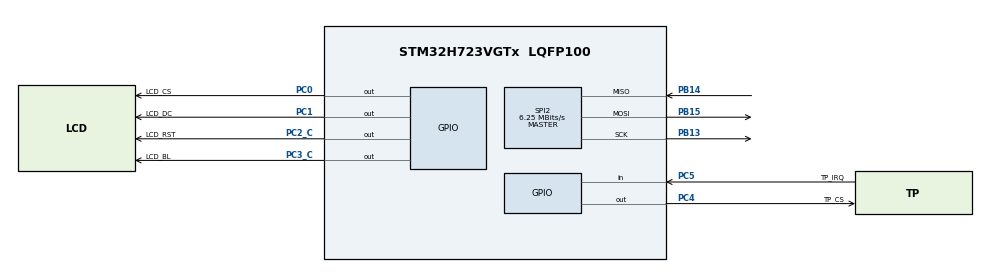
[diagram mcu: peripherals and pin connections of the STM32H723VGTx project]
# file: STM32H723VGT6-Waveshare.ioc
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CORTEX_M7.default_mode_Activation=1
Mcu.Family=STM32H7
Mcu.Name=STM32H723VGTx
Mcu.Package=LQFP100
NVIC.PriorityGroup=NVIC_PRIORITYGROUP_4
PA13(JTMS/SWDIO).Mode=Serial_Wire
PA13(JTMS/SWDIO).Signal=DEBUG_JTMS-SWDIO
PA14(JTCK/SWCLK).Mode=Serial_Wire
PA14(JTCK/SWCLK).Signal=DEBUG_JTCK-SWCLK
PB13.GPIO_Speed=GPIO_SPEED_FREQ_LOW
PB13.Mode=Full_Duplex_Master
PB13.Signal=SPI2_SCK
PB14.GPIO_Speed=GPIO_SPEED_FREQ_LOW
PB14.Mode=Full_Duplex_Master
PB14.Signal=SPI2_MISO
PB15.GPIO_Speed=GPIO_SPEED_FREQ_LOW
PB15.Mode=Full_Duplex_Master
PB15.Signal=SPI2_MOSI
PC0.GPIO_Label=LCD_CS
PC0.GPIO_Speed=GPIO_SPEED_FREQ_LOW
PC0.PinState=GPIO_PIN_RESET
PC0.Signal=GPIO_Output
PC1.GPIO_Label=LCD_DC
PC1.GPIO_Speed=GPIO_SPEED_FREQ_LOW
PC1.Signal=GPIO_Output
PC2_C.GPIO_Label=LCD_RST
PC2_C.Signal=GPIO_Output
PC3_C.GPIO_Label=LCD_BL
PC3_C.Signal=GPIO_Output
PC4.GPIO_Label=TP_CS
PC4.Signal=GPIO_Output
PC5.GPIO_Label=TP_IRQ
PC5.GPIO_PuPd=GPIO_PULLUP
PC5.Signal=GPIO_Input
PH0-OSC_IN.Mode=HSE-External-Oscillator
PH0-OSC_IN.Signal=RCC_OSC_IN
PH1-OSC_OUT.Mode=HSE-External-Oscillator
PH1-OSC_OUT.Signal=RCC_OSC_OUT
ProjectManager.HeapSize=0x200
ProjectManager.StackSize=0x400
ProjectManager.TargetToolchain=STM32CubeIDE
RCC.ADCFreq_Value=50390625
RCC.APB1Freq_Value=100000000
RCC.APB2Freq_Value=100000000
RCC.APB3Freq_Value=100000000
RCC.APB4Freq_Value=100000000
RCC.CortexFreq_Value=400000000
RCC.D1PPRE=RCC_APB3_DIV2
RCC.D2PPRE1=RCC_APB1_DIV2
RCC.D2PPRE2=RCC_APB2_DIV2
RCC.D3PPRE=RCC_APB4_DIV2
RCC.DIVM1=2
RCC.DIVN1=32
RCC.DIVP1=1
RCC.HCLKFreq_Value=200000000
RCC.HPRE=RCC_HCLK_DIV2
RCC.PLL2FRACN=0
RCC.PLL3FRACN=0
RCC.PLLFRACN=0
RCC.PLLSourceVirtual=RCC_PLLSOURCE_HSE
RCC.SYSCLKFreq_VALUE=400000000
RCC.SYSCLKSource=RCC_SYSCLKSOURCE_PLLCLK
RCC.USBFreq_Value=200000000
SPI2.BaudRatePrescaler=SPI_BAUDRATEPRESCALER_32
SPI2.CalculateBaudRate=6.25 MBits/s
SPI2.DataSize=SPI_DATASIZE_8BIT
SPI2.Direction=SPI_DIRECTION_2LINES
SPI2.Mode=SPI_MODE_MASTER
SPI2.VirtualType=VM_MASTER
VP_MEMORYMAP_VS_MEMORYMAP.Mode=CurAppReg
board=custom

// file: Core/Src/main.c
/* USER CODE BEGIN Header */
/**
  ******************************************************************************
  * @file           : main.c
  * @brief          : Main program body
  ******************************************************************************
  * @attention
  *
  * Copyright (c) 2026 STMicroelectronics.
  * All rights reserved.
  *
  * This software is licensed under terms that can be found in the LICENSE file
  * in the root directory of this software component.
  * If no LICENSE file comes with this software, it is provided AS-IS.
  *
  ******************************************************************************
  */
/* USER CODE END Header */
#include "main.h"

/* USER CODE BEGIN Includes */
#include "lcd_ili9486.h"
/* USER CODE END Includes */

SPI_HandleTypeDef hspi2;

/* USER CODE BEGIN PV */
volatile uint8_t lcd_id[3] = { 0, 0, 0 };
volatile uint16_t tp_x = 0, tp_y = 0;
/* USER CODE END PV */

void SystemClock_Config(void);
static void MPU_Config(void);
static void MX_GPIO_Init(void);
static void MX_SPI2_Init(void);

int main(void)
{

  /* MPU Configuration--------------------------------------------------------*/
  MPU_Config();

  /* MCU Configuration--------------------------------------------------------*/

  /* Reset of all peripherals, Initializes the Flash interface and the Systick. */
  HAL_Init();

  /* Configure the system clock */
  SystemClock_Config();

  /* Initialize all configured peripherals */
  MX_GPIO_Init();
  MX_SPI2_Init();
  /* USER CODE BEGIN 2 */
  LCD_Init();
  LCD_ReadID((uint8_t *)lcd_id);
  __NOP(); /* <-- поставить брейкпоинт на эту строку, здесь уже готов lcd_id[0..2] */
  /* USER CODE END 2 */

  /* Infinite loop */
  while (1)
  {

    /* USER CODE BEGIN 3 */
    /* Тач временно отключён на время теста экрана (см. PRIZMA-DOSTOVERNOSTI.md) —
     * TP_ReadRaw() и LCD_FillScreen() делят одну физическую шину SCLK/MOSI (только CS разный),
     * не хотим добавлять лишнюю непроверенную переменную в тест заливки. Раскомментировать,
     * когда вернёмся к диагностике тача.
    TP_ReadRaw((uint16_t *)&tp_x, (uint16_t *)&tp_y);
    HAL_Delay(100);
    */

    LCD_FillScreen(COLOR_RED);
    HAL_Delay(1000);
    LCD_FillScreen(COLOR_GREEN);
    HAL_Delay(1000);
    LCD_FillScreen(COLOR_BLUE);
    HAL_Delay(1000);
  }
  /* USER CODE END 3 */
}

void SystemClock_Config(void)
{
  RCC_OscInitTypeDef RCC_OscInitStruct = {0};
  RCC_ClkInitTypeDef RCC_ClkInitStruct = {0};

  /** Supply configuration update enable
  */
  HAL_PWREx_ConfigSupply(PWR_LDO_SUPPLY);

  /** Configure the main internal regulator output voltage
  */
  __HAL_PWR_VOLTAGESCALING_CONFIG(PWR_REGULATOR_VOLTAGE_SCALE1);

  while(!__HAL_PWR_GET_FLAG(PWR_FLAG_VOSRDY)) {}

  /** Initializes the RCC Oscillators according to the specified parameters
  * in the RCC_OscInitTypeDef structure.
  */
  RCC_OscInitStruct.OscillatorType = RCC_OSCILLATORTYPE_HSE;
  RCC_OscInitStruct.HSEState = RCC_HSE_ON;
  RCC_OscInitStruct.PLL.PLLState = RCC_PLL_ON;
  RCC_OscInitStruct.PLL.PLLSource = RCC_PLLSOURCE_HSE;
  RCC_OscInitStruct.PLL.PLLM = 2;
  RCC_OscInitStruct.PLL.PLLN = 32;
  RCC_OscInitStruct.PLL.PLLP = 1;
  RCC_OscInitStruct.PLL.PLLQ = 2;
  RCC_OscInitStruct.PLL.PLLR = 2;
  RCC_OscInitStruct.PLL.PLLRGE = RCC_PLL1VCIRANGE_3;
  RCC_OscInitStruct.PLL.PLLVCOSEL = RCC_PLL1VCOWIDE;
  RCC_OscInitStruct.PLL.PLLFRACN = 0;
  if (HAL_RCC_OscConfig(&RCC_OscInitStruct) != HAL_OK)
  {
    Error_Handler();
  }

  /** Initializes the CPU, AHB and APB buses clocks
  */
  RCC_ClkInitStruct.ClockType = RCC_CLOCKTYPE_HCLK|RCC_CLOCKTYPE_SYSCLK
                              |RCC_CLOCKTYPE_PCLK1|RCC_CLOCKTYPE_PCLK2
                              |RCC_CLOCKTYPE_D3PCLK1|RCC_CLOCKTYPE_D1PCLK1;
  RCC_ClkInitStruct.SYSCLKSource = RCC_SYSCLKSOURCE_PLLCLK;
  RCC_ClkInitStruct.SYSCLKDivider = RCC_SYSCLK_DIV1;
  RCC_ClkInitStruct.AHBCLKDivider = RCC_HCLK_DIV2;
  RCC_ClkInitStruct.APB3CLKDivider = RCC_APB3_DIV2;
  RCC_ClkInitStruct.APB1CLKDivider = RCC_APB1_DIV2;
  RCC_ClkInitStruct.APB2CLKDivider = RCC_APB2_DIV2;
  RCC_ClkInitStruct.APB4CLKDivider = RCC_APB4_DIV2;

  if (HAL_RCC_ClockConfig(&RCC_ClkInitStruct, FLASH_LATENCY_2) != HAL_OK)
  {
    Error_Handler();
  }
}

static void MX_SPI2_Init(void)
{

  /* SPI2 parameter configuration*/
  hspi2.Instance = SPI2;
  hspi2.Init.Mode = SPI_MODE_MASTER;
  hspi2.Init.Direction = SPI_DIRECTION_2LINES;
  hspi2.Init.DataSize = SPI_DATASIZE_8BIT;
  hspi2.Init.CLKPolarity = SPI_POLARITY_LOW;
  hspi2.Init.CLKPhase = SPI_PHASE_1EDGE;
  hspi2.Init.NSS = SPI_NSS_SOFT;
  hspi2.Init.BaudRatePrescaler = SPI_BAUDRATEPRESCALER_32;
  hspi2.Init.FirstBit = SPI_FIRSTBIT_MSB;
  hspi2.Init.TIMode = SPI_TIMODE_DISABLE;
  hspi2.Init.CRCCalculation = SPI_CRCCALCULATION_DISABLE;
  hspi2.Init.CRCPolynomial = 0x0;
  hspi2.Init.NSSPMode = SPI_NSS_PULSE_ENABLE;
  hspi2.Init.NSSPolarity = SPI_NSS_POLARITY_LOW;
  hspi2.Init.FifoThreshold = SPI_FIFO_THRESHOLD_01DATA;
  hspi2.Init.TxCRCInitializationPattern = SPI_CRC_INITIALIZATION_ALL_ZERO_PATTERN;
  hspi2.Init.RxCRCInitializationPattern = SPI_CRC_INITIALIZATION_ALL_ZERO_PATTERN;
  hspi2.Init.MasterSSIdleness = SPI_MASTER_SS_IDLENESS_00CYCLE;
  hspi2.Init.MasterInterDataIdleness = SPI_MASTER_INTERDATA_IDLENESS_00CYCLE;
  hspi2.Init.MasterReceiverAutoSusp = SPI_MASTER_RX_AUTOSUSP_DISABLE;
  hspi2.Init.MasterKeepIOState = SPI_MASTER_KEEP_IO_STATE_DISABLE;
  hspi2.Init.IOSwap = SPI_IO_SWAP_DISABLE;
  if (HAL_SPI_Init(&hspi2) != HAL_OK)
  {
    Error_Handler();
  }

}

static void MX_GPIO_Init(void)
{
  GPIO_InitTypeDef GPIO_InitStruct = {0};

  /* GPIO Ports Clock Enable */
  __HAL_RCC_GPIOH_CLK_ENABLE();
  __HAL_RCC_GPIOC_CLK_ENABLE();
  __HAL_RCC_GPIOB_CLK_ENABLE();
  __HAL_RCC_GPIOA_CLK_ENABLE();

  /*Configure GPIO pin Output Level */
  HAL_GPIO_WritePin(GPIOC, LCD_CS_Pin|LCD_DC_Pin|LCD_RST_Pin|LCD_BL_Pin
                          |TP_CS_Pin, GPIO_PIN_RESET);

  /*Configure GPIO pins : LCD_CS_Pin LCD_DC_Pin LCD_RST_Pin LCD_BL_Pin
                           TP_CS_Pin */
  GPIO_InitStruct.Pin = LCD_CS_Pin|LCD_DC_Pin|LCD_RST_Pin|LCD_BL_Pin
                          |TP_CS_Pin;
  GPIO_InitStruct.Mode = GPIO_MODE_OUTPUT_PP;
  GPIO_InitStruct.Pull = GPIO_NOPULL;
  GPIO_InitStruct.Speed = GPIO_SPEED_FREQ_LOW;
  HAL_GPIO_Init(GPIOC, &GPIO_InitStruct);

  /*Configure GPIO pin : TP_IRQ_Pin */
  GPIO_InitStruct.Pin = TP_IRQ_Pin;
  GPIO_InitStruct.Mode = GPIO_MODE_INPUT;
  GPIO_InitStruct.Pull = GPIO_PULLUP;
  HAL_GPIO_Init(TP_IRQ_GPIO_Port, &GPIO_InitStruct);

  /*AnalogSwitch Config */
  HAL_SYSCFG_AnalogSwitchConfig(SYSCFG_SWITCH_PC2, SYSCFG_SWITCH_PC2_CLOSE);

  /*AnalogSwitch Config */
  HAL_SYSCFG_AnalogSwitchConfig(SYSCFG_SWITCH_PC3, SYSCFG_SWITCH_PC3_CLOSE);

}

 /* MPU Configuration */

void MPU_Config(void)
{
  MPU_Region_InitTypeDef MPU_InitStruct = {0};

  /* Disables the MPU */
  HAL_MPU_Disable();

  /** Initializes and configures the Region and the memory to be protected
  */
  MPU_InitStruct.Enable = MPU_REGION_ENABLE;
  MPU_InitStruct.Number = MPU_REGION_NUMBER0;
  MPU_InitStruct.BaseAddress = 0x0;
  MPU_InitStruct.Size = MPU_REGION_SIZE_4GB;
  MPU_InitStruct.SubRegionDisable = 0x87;
  MPU_InitStruct.TypeExtField = MPU_TEX_LEVEL0;
  MPU_InitStruct.AccessPermission = MPU_REGION_NO_ACCESS;
  MPU_InitStruct.DisableExec = MPU_INSTRUCTION_ACCESS_DISABLE;
  MPU_InitStruct.IsShareable = MPU_ACCESS_SHAREABLE;
  MPU_InitStruct.IsCacheable = MPU_ACCESS_NOT_CACHEABLE;
  MPU_InitStruct.IsBufferable = MPU_ACCESS_NOT_BUFFERABLE;

  HAL_MPU_ConfigRegion(&MPU_InitStruct);
  /* Enables the MPU */
  HAL_MPU_Enable(MPU_PRIVILEGED_DEFAULT);

}

void Error_Handler(void)
{
  __disable_irq();
  while (1)
  {
  }
}
